# NANO100BN_v1 register map
File version: 1.0
Registers are 32-bit, read-write, reset 0x0 unless marked. A register's access mark holds for its fields unless they carry their own. Offsets are from the block's base; [hi:lo] are bit positions; 'fields as' and 'values as' point back to an identical list.

## I2C0 — I2C Register Map
Base 0x40020000
Same registers: I2C1 0x40120000
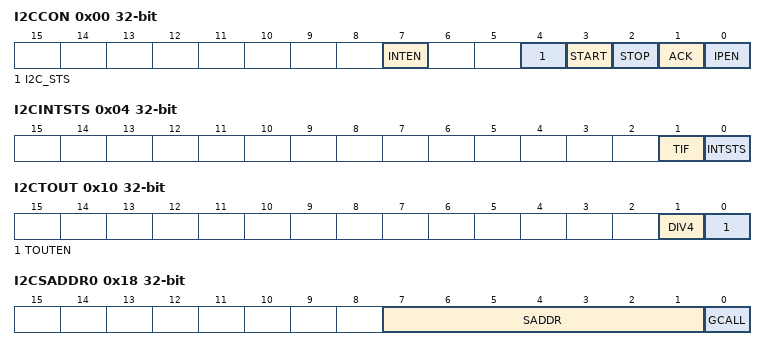
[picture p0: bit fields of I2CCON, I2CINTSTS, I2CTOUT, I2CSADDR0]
0x00 I2CCON — I2C Control Register
  [7] INTEN — Interrupt Enable.
    0=I2C interrupt Disabled; 1=I2C interrupt Enabled
  [4] I2C_STS — I2C Status. When a new state is present in the I2CSTATUS register, this bit will be set automatically, and if the INTEN bit is set, the I2C interrupt is requested. It must be cleared by software by writing one to this bit and the I2C protocol function will go ahead until the STOP is active or the IPEN is disabled
    0=I2C's Status disabled and the I2C protocol function will go ahead; 1=I2C's Status active
  [3] START — I2C START Command. Setting this bit to 1 to enter Master mode, the device sends a START or repeat START condition to bus when the bus is free and it will be cleared to 0 after the START command is active and the STATUS has been updated.
    0=After START or repeat START is active; 1=Sends a START or repeat START condition to bus
  [2] STOP — I2C STOP Control Bit. In Master mode, set this bit to 1 to transmit a STOP condition to bus then the controller will check the bus condition if a STOP condition is detected and this bit will be cleared by hardware automatically. In Slave mode, set this bit to 1 to reset the controller to the defined "not addressed" Slave mode. This means it is NO LONGER in the slave receiver mode to receive data from the master transmit device.
    0=Will be cleared by hardware automatically if a STOP condition is detected; 1=Sends a STOP condition to bus in Master mode or reset the controller to "not addressed" in Slave mode
  [1] ACK — Assert Acknowledge Control Bit
    0=: When this bit is set to 0 prior to address or data received, a Not acknowledged (high level to SDA) will be returned during the acknowledge clock pulse; 1=When this bit is set to 1 prior to address or data received, an acknowledged will be returned during the acknowledge clock pulse on the SCL line when
  [0] IPEN — I2C Function Enable. When this bit is set to 1, the I2C serial function is enabled.
    0=I2C function Disabled; 1=I2C function Enabled
0x04 I2CINTSTS — I2C Interrupt Status Register
  [1] TIF — Time-out Status
    0=No Time-out flag. Software can cleat this flag; 1=Time-Out flag active and it is set by hardware
  [0] INTSTS — I2S STATUS's Interrupt Status. When a new state is present in the I2CSTATUS register, this bit will be set automatically, and if INTEN bit is set, the I2C interrupt is requested. Software can write one to cleat this bit.
0x08 I2CSTATUS ro reset 0xF8
  [7:0] STATUS — I2C Status Register. In addition, states 00H stands for a 'Bus Error'. A 'Bus Error' occurs when a START or STOP condition is present at an illegal position in the formation frame. Example of illegal position: a data byte or an acknowledge bit is present during the serial transfer of an address byte. To recover I2C from bus error, STOP should be set and I2C_STS should be cleared to enter not addressed Slave mode. Then clear STOP to release the bus and to wait new communication. I2C bus can not recognize stop condition during this action when bus error occurs.
0x0C I2CDIV — I2C clock divided Register
  [7:0] CLK_DIV — I2C Clock Divider
0x10 I2CTOUT — I2C Time-out control Register
  [1] DIV4 — Time-Out Counter Input Clock Divider by 4. When this bit is set enabled, the Time-Out period is prolonging 4 times.
    0=Disabled; 1=Enabled
  [0] TOUTEN — Time-out Counter Enable/Disable. When set this bit to enable, the 14 bits time-out counter will start counting when STAINTSTS is cleared. Setting flag STAINTSTS to high or the falling edge of I2C clock or stop signal will reset counter and re-start up counting after STAINTSTS is cleared.
    0=Disabled; 1=Enabled
0x14 I2CDATA
  [7:0] DATA — I2C Data Register. The DATA contains a byte of serial data to be transmitted or a byte which has just been received. The user can read from or write to this 8-bit I2CDATA register directly while it is not in the process of shifting a byte. This occurs when the serial interrupt flag is set. Data in DATA remains stable as long as I2C_STS bit is set. While data is being shifted out, data on the bus is simultaneously being shifted in; The DATA always contains the last data byte present on the bus. Thus, in the event of arbitration lost, the transition from master transmitter to slave receiver is made with the correct data in DATA. DATA and the acknowledge bit form a 9-bit shift register, the acknowledge bit is controlled by the device hardware and cannot be accessed by the user. Serial data is shifted through the acknowledge bit into DATA on the rising edges of serial clock pulses on the SCL line. When a byte has been shifted into DATA, the serial data is available in DATA, and the acknowledge bit (ACK or NACK) is returned by the control logic during the ninth clock pulse.
0x18 I2CSADDR0 — I2C Slave address Register0
  [7:1] SADDR — I2C Salve Address Register. The content of this register is irrelevant when the device is in Master mode. In the Slave mode, the seven most significant bits must be loaded with the device's own address. The device will react if either of the address is matched.
  [0] GCALL — General Call Function. The I2C controller supports the "General Call" function. If the GCALL bit is set, the controller will respond to General Call address (00H). When GCALL bit is set, the controller is in Slave mode, it can receive the general call address by 00H after Master send general call address to the I2C bus, then it will follow status of GCALL mode. If it is in Master mode, the ACK bit must be cleared when it will send general call address of 00H to I2C bus.
    0=General Call Function Disabled; 1=General Call Function Enabled
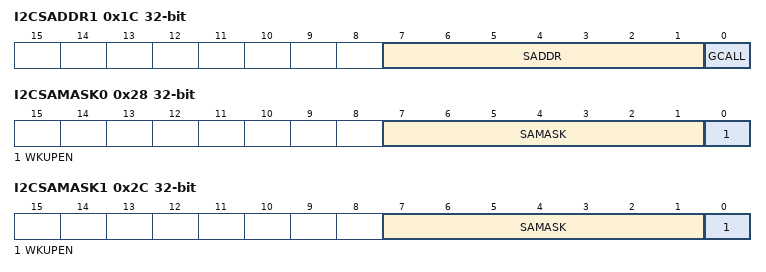
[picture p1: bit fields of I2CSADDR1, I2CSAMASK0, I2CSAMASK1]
0x1C I2CSADDR1 — I2C Slave address Register1
  fields as I2CSADDR0
0x28 I2CSAMASK0 — I2C Slave address Mask Register0
  [7:1] SAMASK — I2C Slave Address Mask Register. I2C bus controllers support multiple address recognition with two address mask registers. When the bit in the address mask register is set to b'1, it means the received corresponding address bit is don't-care. If the bit is set to b'0, that means the received corresponding register bit should be exact the same as address register.
    0=Mask disable (the received corresponding register bit should be exact the same as address register.); 1=Mask enable (the received corresponding address bit is don't care.)
  [0] WKUPEN — I2C Wake-up Function Enable
    0=I2C wake-up function Disabled; 1=I2C wake-up function Enabled
0x2C I2CSAMASK1 — I2C Slave address Mask Register1
  fields as I2CSAMASK0
0x3C I2CWKUPCON — I2C Wake-up Control Register
  [0] WKUPEN — I2C Wake-up Function Enable
    values as I2CSAMASK0.WKUPEN
0x40 I2CWKUPSTS ro — I2C Wake-up Status Register
  [0] WKUPIF — Wake-up Interrupt Flag. Software can write one to clear this flag
    0=Wake-up flag inactive; 1=Wake-up flag active
